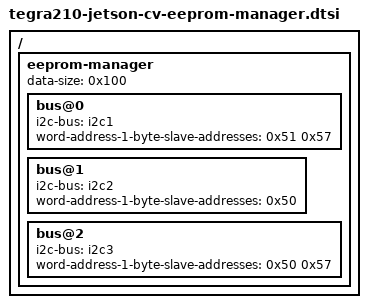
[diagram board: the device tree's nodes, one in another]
/*
 * Copyright (c) 2015, NVIDIA CORPORATION.  All rights reserved.
 *
 * This program is free software; you can redistribute it and/or modify
 * it under the terms of the GNU General Public License as published by
 * the Free Software Foundation; version 2 of the License.
 *
 * This program is distributed in the hope that it will be useful, but WITHOUT
 * ANY WARRANTY; without even the implied warranty of MERCHANTABILITY or
 * FITNESS FOR A PARTICULAR PURPOSE.  See the GNU General Public License for
 * more details.
 *
 */

/ {
	eeprom-manager {
		data-size = <0x100>;
		bus@0 {
			i2c-bus = <&i2c1>;
			word-address-1-byte-slave-addresses = <0x51 0x57>;
		};
		bus@1 {
			i2c-bus = <&i2c2>;
			word-address-1-byte-slave-addresses = <0x50>;
		};
		bus@2 {
			i2c-bus = <&i2c3>;
			word-address-1-byte-slave-addresses = <0x50 0x57>;
		};
	};
};
